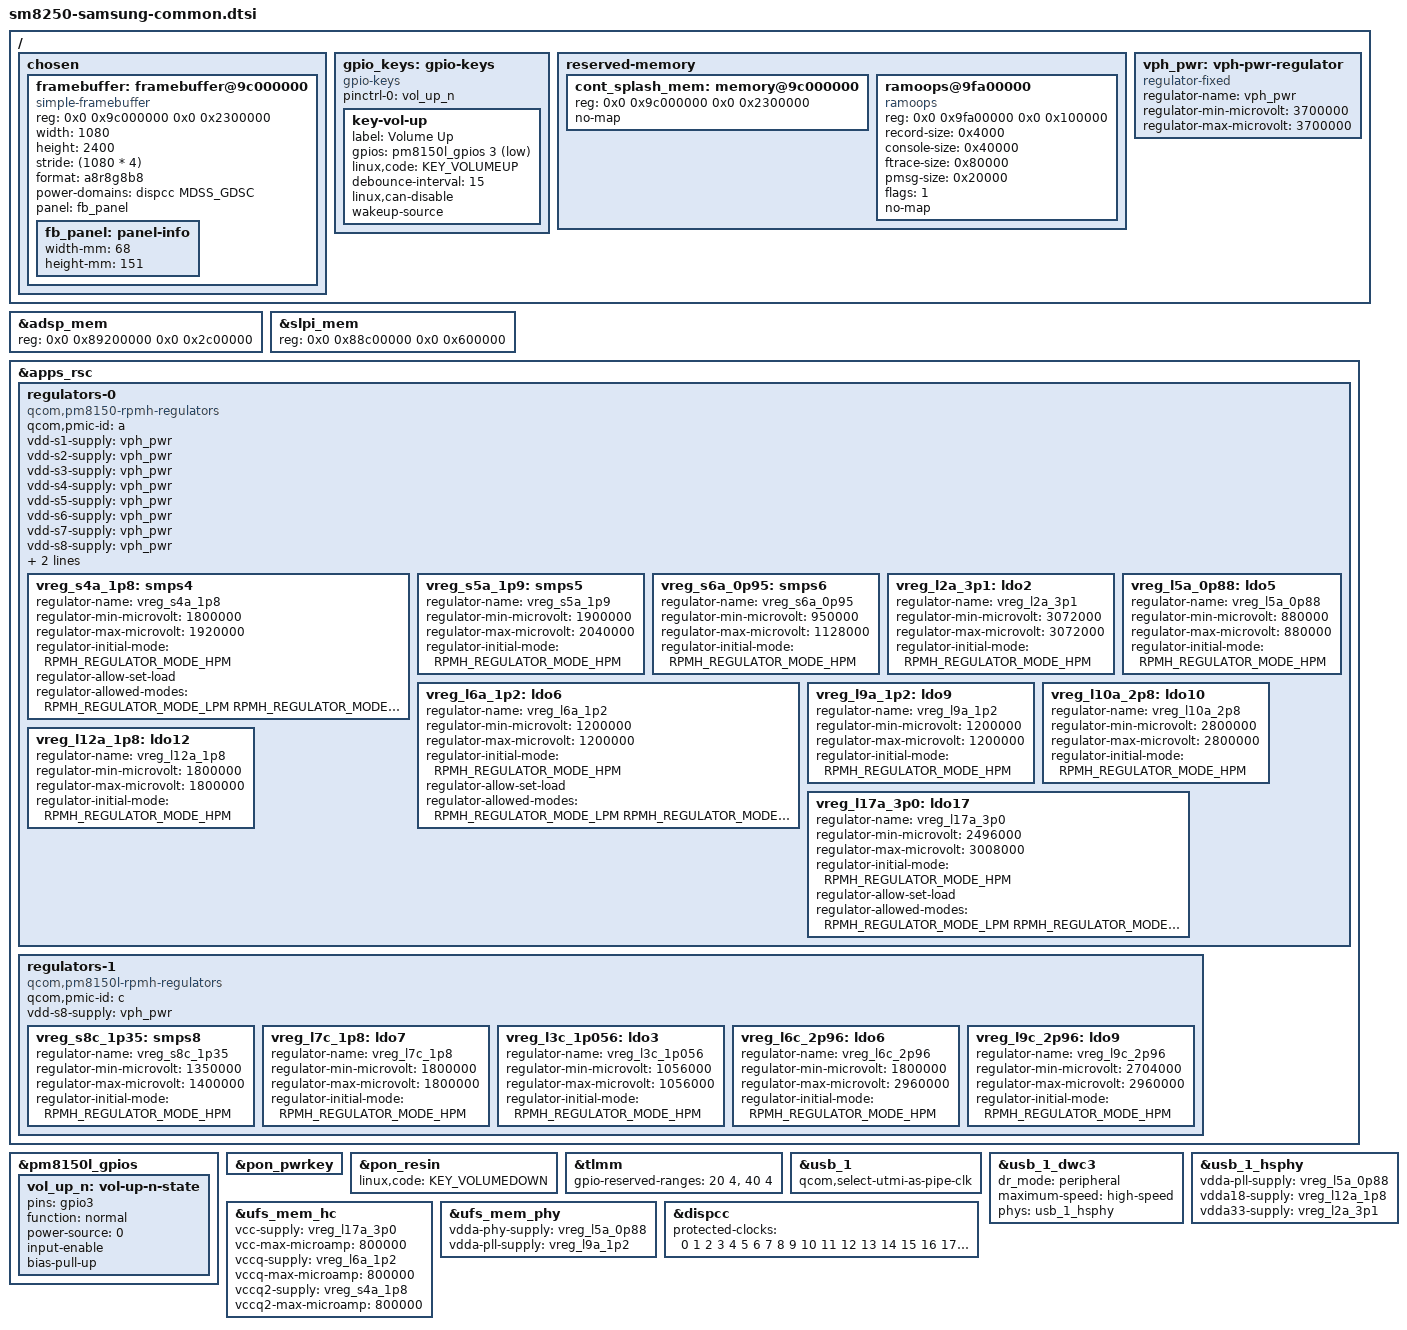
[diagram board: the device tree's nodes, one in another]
// SPDX-License-Identifier: GPL-2.0-only

/dts-v1/;

#include <dt-bindings/regulator/qcom,rpmh-regulator.h>
#include "sm8250.dtsi"
#include "pm8150.dtsi"
#include "pm8150l.dtsi"

/ {
	chosen {
		#address-cells = <2>;
		#size-cells = <2>;
		ranges;

		framebuffer: framebuffer@9c000000 {
			compatible = "simple-framebuffer";
			reg = <0x0 0x9c000000 0x0 0x2300000>;
			width = <1080>;
			height = <2400>;
			stride = <(1080 * 4)>;
			format = "a8r8g8b8";
			/*
			 * Hold MDSS GDSC on. Samsung UEFI leaves the DPU scanning
			 * out of this buffer; Linux otherwise powers off mdss_gdsc
			 * at ~13.3 s (pd_ignore_unused does NOT cover it) and the
			 * panel freezes. Making simpledrm an active consumer of
			 * MDSS_GDSC keeps genpd from gating it. Clocks are handled
			 * via dispcc protected-clocks -> NO clocks here (adding
			 * clocks to this node hangs boot, see history).
			 */
			power-domains = <&dispcc MDSS_GDSC>;

			/*
			 * Give simpledrm a real physical size so mutter stops
			 * guessing "27 inch" and can size-match the touchscreen to
			 * this output. EA8076A/AMS646UJ10 is a 6.5" 1080x2400 panel
			 * (~68 x 151 mm). Paired with the DSI connector-type patch
			 * (simpledrm reports DRM_MODE_CONNECTOR_DSI), mutter then
			 * treats this as a builtin panel and maps the internal
			 * touchscreen to it -- so touch follows display rotation.
			 */
			panel = <&fb_panel>;

			fb_panel: panel-info {
				width-mm = <68>;
				height-mm = <151>;
			};
		};
	};

	gpio_keys: gpio-keys {
		compatible = "gpio-keys";

		pinctrl-names = "default";
		pinctrl-0 = <&vol_up_n>;

		key-vol-up {
			label = "Volume Up";
			/*
			 * The physical Vol-Up button is on pm8150L gpio3, NOT
			 * pm8150 gpio3 (confirmed from the stock DT). Mainline's
			 * original pm8150_gpios wiring meant the key never fired.
			 */
			gpios = <&pm8150l_gpios 3 GPIO_ACTIVE_LOW>;
			linux,code = <KEY_VOLUMEUP>;
			debounce-interval = <15>;
			linux,can-disable;
			wakeup-source;
		};
	};

	reserved-memory {
		cont_splash_mem: memory@9c000000 {
			reg = <0x0 0x9c000000 0x0 0x2300000>;
			no-map;
		};

		ramoops@9fa00000 {
			compatible = "ramoops";
			reg = <0x0 0x9fa00000 0x0 0x100000>;
			record-size = <0x4000>;
			console-size = <0x40000>;
			ftrace-size = <0x80000>;
			pmsg-size = <0x20000>;
			/*
			 * BIT(0) = RAMOOPS_FLAG_FTRACE_PER_CPU, and it is not optional
			 * here. Only ramoops' platform-data path sets it by default; the
			 * DT path reads it from this property, so without it
			 * ramoops_pstore_write() sends EVERY cpu's function trace into
			 * fprzs[0] behind one raw_spinlock. The lock path is itself
			 * traced, so turning on /sys/kernel/debug/pstore/record_ftrace
			 * livelocks the machine: on 2026-09-07 it hung the phone hard
			 * within seconds, and the recovered ring was nothing but
			 * "_raw_spin_lock_irqsave <- persistent_ram_write".
			 * With the flag set each cpu gets its own zone and
			 * PRZ_FLAG_NO_LOCK, i.e. a lockless per-cpu ring.
			 *
			 * ftrace 512K/8 = 64K per cpu = ~2700 records, which is the
			 * only channel that shows what the WEDGED core itself was doing
			 * (it answers no IPI and no NMI, so nothing can interrogate it
			 * after the fact). pmsg drops to 128K to pay for it -- still
			 * ~30 min of 10 ms watchdog heartbeats.
			 */
			flags = <1>;
			no-map;
		};
	};
};

/*
 * r8q: Samsung's signed ADSP image does not fit mainline's carveout.
 *
 * sm8250.dtsi sizes adsp_mem at 0x1d00000 (29.00 MiB), which is EXACTLY the span of the
 * generic linux-firmware sm8250 adsp.mbn. Samsung's own signed image carries a lot more
 * codecs (ALAC/APE/FLAC/LDAC/WMA/AudioSphere -- see the stock `dsp` partition) and spans
 * 44.00 MiB of PT_LOAD segments (0x89500000-0x8c100000, all relocatable, bit 27 set):
 *
 *   linux-firmware generic  19 segs  0x89500000-0x8b200000 = 29.00 MiB
 *   Samsung r8q             20 segs  0x89500000-0x8c100000 = 44.00 MiB
 *
 * With only 29 MiB, qcom_mdt_load bails out per-segment with "segment outside memory range"
 * (offset + p_memsz > mem_size) and the ADSP never boots -- which means no q6afe/q6asm/
 * q6routing, i.e. no audio at all.
 *
 * We give the ADSP the SLPI slot as well, since we do not use the sensor DSP.
 *
 * IMPORTANT -- the region may NOT start at 0x88c00000, even though that is where slpi_mem
 * begins and it looks like the obvious place. Something in the pre-Linux environment (almost
 * certainly Mu-Silicium's EFI memory map) claims physical memory up to 0x891fffff, and that
 * claim does NOT track our device tree:
 *
 *   /proc/iomem:  86e00000-891fffff : reserved
 *
 * Anything requesting a region that starts inside it gets
 * "-EBUSY: can't request region for resource" out of devm_ioremap_wc and the driver never
 * even reaches the firmware. That is why upstream's slpi_mem at 0x88c00000 always failed
 * this way, while adsp_mem at 0x8a100000 got all the way to the firmware size check -- it
 * sits above the claim. So the region must start at or above 0x89200000.
 *
 * 0x89200000..0x8be00000 is exactly 0x2c00000 = 44.00 MiB, which is exactly the span the
 * Samsung image needs. mdt_loader's per-segment test is
 * "offset + p_memsz > mem_size", so an exact fit passes. spss_mem and cdsp_secure_heap are
 * deliberately left where upstream puts them rather than shuffled for headroom -- they are
 * TZ-facing regions and not worth disturbing for one spare megabyte.
 *
 *   cdsp_mem  0x87800000 + 0x1400000 -> 0x88c00000   (unchanged)
 *   slpi_mem  0x88c00000 +  0x600000 -> 0x89200000   (parked in the claimed zone, &slpi off)
 *   adsp_mem  0x89200000 + 0x2c00000 -> 0x8be00000   (was 0x8a100000 + 0x1d00000)
 *   spss_mem  0x8be00000 +  0x100000 -> 0x8bf00000   (unchanged)
 */
&adsp_mem {
	reg = <0x0 0x89200000 0x0 0x2c00000>;
};

&slpi_mem {
	reg = <0x0 0x88c00000 0x0 0x600000>;
};

/ {

	vph_pwr: vph-pwr-regulator {
		compatible = "regulator-fixed";
		regulator-name = "vph_pwr";
		regulator-min-microvolt = <3700000>;
		regulator-max-microvolt = <3700000>;
	};
};

&apps_rsc {
	regulators-0 {
		compatible = "qcom,pm8150-rpmh-regulators";
		qcom,pmic-id = "a";

		vdd-s1-supply = <&vph_pwr>;
		vdd-s2-supply = <&vph_pwr>;
		vdd-s3-supply = <&vph_pwr>;
		vdd-s4-supply = <&vph_pwr>;
		vdd-s5-supply = <&vph_pwr>;
		vdd-s6-supply = <&vph_pwr>;
		vdd-s7-supply = <&vph_pwr>;
		vdd-s8-supply = <&vph_pwr>;
		vdd-s9-supply = <&vph_pwr>;
		vdd-s10-supply = <&vph_pwr>;

		vreg_s4a_1p8: smps4 {
			regulator-name = "vreg_s4a_1p8";
			regulator-min-microvolt = <1800000>;
			regulator-max-microvolt = <1920000>;
			regulator-initial-mode = <RPMH_REGULATOR_MODE_HPM>;
			regulator-allow-set-load;
			regulator-allowed-modes = <RPMH_REGULATOR_MODE_LPM
						   RPMH_REGULATOR_MODE_HPM>;
		};

		/* S5A/S6A feed the QCA6390 WiFi/BT PMU (vddrfa1p9, vddaon/pmu). */
		vreg_s5a_1p9: smps5 {
			regulator-name = "vreg_s5a_1p9";
			regulator-min-microvolt = <1900000>;
			regulator-max-microvolt = <2040000>;
			regulator-initial-mode = <RPMH_REGULATOR_MODE_HPM>;
		};

		vreg_s6a_0p95: smps6 {
			regulator-name = "vreg_s6a_0p95";
			regulator-min-microvolt = <950000>;
			regulator-max-microvolt = <1128000>;
			regulator-initial-mode = <RPMH_REGULATOR_MODE_HPM>;
		};

		vreg_l2a_3p1: ldo2 {
			regulator-name = "vreg_l2a_3p1";
			regulator-min-microvolt = <3072000>;
			regulator-max-microvolt = <3072000>;
			regulator-initial-mode = <RPMH_REGULATOR_MODE_HPM>;
		};

		vreg_l5a_0p88: ldo5 {
			regulator-name = "vreg_l5a_0p88";
			regulator-min-microvolt = <880000>;
			regulator-max-microvolt = <880000>;
			regulator-initial-mode = <RPMH_REGULATOR_MODE_HPM>;
		};

		vreg_l6a_1p2: ldo6 {
			regulator-name = "vreg_l6a_1p2";
			regulator-min-microvolt = <1200000>;
			regulator-max-microvolt = <1200000>;
			regulator-initial-mode = <RPMH_REGULATOR_MODE_HPM>;
			regulator-allow-set-load;
			regulator-allowed-modes = <RPMH_REGULATOR_MODE_LPM
						   RPMH_REGULATOR_MODE_HPM>;
		};

		vreg_l9a_1p2: ldo9 {
			regulator-name = "vreg_l9a_1p2";
			regulator-min-microvolt = <1200000>;
			regulator-max-microvolt = <1200000>;
			regulator-initial-mode = <RPMH_REGULATOR_MODE_HPM>;
		};

		/*
		 * Camera autofocus actuator supply (stock cam_vaf on every
		 * qcom,actuator node). 2.8 V is selector 162 of this PLDO's
		 * 1.504 V + 8 mV range, so unlike the 1.05 V front-camera rail
		 * it lands exactly on the grid.
		 */
		vreg_l10a_2p8: ldo10 {
			regulator-name = "vreg_l10a_2p8";
			regulator-min-microvolt = <2800000>;
			regulator-max-microvolt = <2800000>;
			regulator-initial-mode = <RPMH_REGULATOR_MODE_HPM>;
		};

		vreg_l12a_1p8: ldo12 {
			regulator-name = "vreg_l12a_1p8";
			regulator-min-microvolt = <1800000>;
			regulator-max-microvolt = <1800000>;
			regulator-initial-mode = <RPMH_REGULATOR_MODE_HPM>;
		};

		vreg_l17a_3p0: ldo17 {
			regulator-name = "vreg_l17a_3p0";
			regulator-min-microvolt = <2496000>;
			regulator-max-microvolt = <3008000>;
			regulator-initial-mode = <RPMH_REGULATOR_MODE_HPM>;
			regulator-allow-set-load;
			regulator-allowed-modes = <RPMH_REGULATOR_MODE_LPM
						   RPMH_REGULATOR_MODE_HPM>;
		};
	};

	/*
	 * pm8150l (RPMh id "c"). Only S8C is wired up so far -- it feeds the
	 * QCA6390 WiFi/BT PMU (vddrfa1p3 / vddpcie1p3). Add more rails here as
	 * other pm8150l-powered blocks get brought up.
	 */
	regulators-1 {
		compatible = "qcom,pm8150l-rpmh-regulators";
		qcom,pmic-id = "c";

		vdd-s8-supply = <&vph_pwr>;

		vreg_s8c_1p35: smps8 {
			regulator-name = "vreg_s8c_1p35";
			regulator-min-microvolt = <1350000>;
			regulator-max-microvolt = <1400000>;
			regulator-initial-mode = <RPMH_REGULATOR_MODE_HPM>;
		};

		/*
		 * Camera I/O rail, 1.8 V. Every camera in the stock dtbo takes
		 * its cam_vio from this LDO (downstream calls the PMIC
		 * "pm8150a", which is this chip -- pm8150L, RPMh id "c": its
		 * rail list has the BOB and the AMOLED regulators, and its l2/l3
		 * are NLDOs, which is what the 1.1 V / 1.05 V camera digital
		 * supplies need).
		 */
		vreg_l7c_1p8: ldo7 {
			regulator-name = "vreg_l7c_1p8";
			regulator-min-microvolt = <1800000>;
			regulator-max-microvolt = <1800000>;
			regulator-initial-mode = <RPMH_REGULATOR_MODE_HPM>;
		};

		/*
		 * Front camera digital core. The stock DT asks for 1.050 V, but
		 * this is an RPMh NLDO whose selectors are 8 mV apart from
		 * 320 mV, so 1,050,000 is not on the grid -- and because
		 * min == max the regulator core has to apply exactly that
		 * voltage at registration, fails, and takes the WHOLE
		 * regulators-1 node down with it (which costs S8C, and with it
		 * WiFi). 1.056 V is the next selector up; mainline sm8550-qrd
		 * names the same rail vreg_l2m_1p056 for the same reason.
		 */
		vreg_l3c_1p056: ldo3 {
			regulator-name = "vreg_l3c_1p056";
			regulator-min-microvolt = <1056000>;
			regulator-max-microvolt = <1056000>;
			regulator-initial-mode = <RPMH_REGULATOR_MODE_HPM>;
		};

		/*
		 * microSD: L6C is the I/O rail (1.8 V <-> 2.96 V, switched for
		 * UHS signalling), L9C is the card supply. Same two rails as
		 * the Qualcomm reference boards; stock calls them
		 * pm8150a_l6 / pm8150a_l9. Both are PLDOs on an 8 mV grid from
		 * 1.504 V, and these limits are on it.
		 */
		vreg_l6c_2p96: ldo6 {
			regulator-name = "vreg_l6c_2p96";
			regulator-min-microvolt = <1800000>;
			regulator-max-microvolt = <2960000>;
			regulator-initial-mode = <RPMH_REGULATOR_MODE_HPM>;
		};

		vreg_l9c_2p96: ldo9 {
			regulator-name = "vreg_l9c_2p96";
			regulator-min-microvolt = <2704000>;
			regulator-max-microvolt = <2960000>;
			regulator-initial-mode = <RPMH_REGULATOR_MODE_HPM>;
		};
	};
};

&pm8150l_gpios {
	vol_up_n: vol-up-n-state {
		pins = "gpio3";
		function = "normal";
		power-source = <0>;
		input-enable;
		bias-pull-up;
	};
};

&pon_pwrkey {
	status = "okay";
};

&pon_resin {
	linux,code = <KEY_VOLUMEDOWN>;
	status = "okay";
};

&tlmm {
	gpio-reserved-ranges = <20 4>, /* SPI (fingerprint scanner) */
			       <40 4>; /* Unused */
};

&usb_1 {
	/* Limit to USB 2.0 for now */
	qcom,select-utmi-as-pipe-clk;

	status = "okay";
};

&usb_1_dwc3 {
	dr_mode = "peripheral";
	maximum-speed = "high-speed";
	/* Remove USB3 phy */
	phys = <&usb_1_hsphy>;
	phy-names = "usb2-phy";
};

&usb_1_hsphy {
	vdda-pll-supply = <&vreg_l5a_0p88>;
	vdda18-supply = <&vreg_l12a_1p8>;
	vdda33-supply = <&vreg_l2a_3p1>;

	status = "okay";
};

&ufs_mem_hc {
	vcc-supply = <&vreg_l17a_3p0>;
	vcc-max-microamp = <800000>;
	vccq-supply = <&vreg_l6a_1p2>;
	vccq-max-microamp = <800000>;
	vccq2-supply = <&vreg_s4a_1p8>;
	vccq2-max-microamp = <800000>;

	status = "okay";
};

&ufs_mem_phy {
	vdda-phy-supply = <&vreg_l5a_0p88>;
	vdda-pll-supply = <&vreg_l9a_1p2>;

	status = "okay";
};


/*
 * Display clock controller: keep it ENABLED (so it probes and fw_devlink is
 * satisfied -- disabling the node hangs early boot, v14), but mark every dispcc
 * clock as protected so the qcom clk driver registers the controller yet NEVER
 * touches these clocks (qcom_cc_drop_protected -> rclks[i]=NULL). This leaves
 * the byte/pixel/mdp/vsync clocks feeding Samsung UEFI's live DSI scanout
 * exactly as firmware set them, so the framebuffer @9c000000 should survive the
 * ~11.6 s probe burst instead of dying. Nothing enabled consumes dispcc (all
 * consumers are under the upstream-disabled mdss@ae00000). (fix2.md §5, surgical.)
 */
&dispcc {
	protected-clocks = <0 1 2 3 4 5 6 7 8 9 10 11 12 13 14 15 16 17 18 19 20 21 22 23 24 25 26 27 28 29 30 31 32 33 34 35 36 37 38 39 40 41 42 43 44 45 46 47 48 49 50 51 52 53 54 55 56 57>;
};
